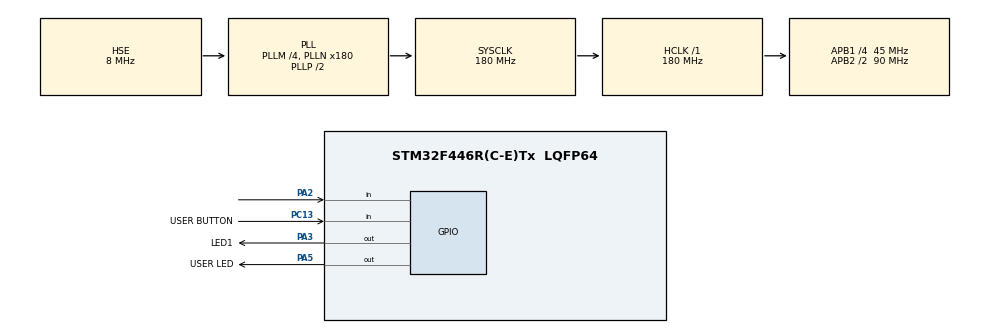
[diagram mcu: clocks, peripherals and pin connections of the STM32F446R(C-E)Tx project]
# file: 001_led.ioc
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Mcu.Family=STM32F4
Mcu.Name=STM32F446R(C-E)Tx
Mcu.Package=LQFP64
NVIC.PriorityGroup=NVIC_PRIORITYGROUP_0
PA2.Signal=GPIO_Input
PA3.GPIO_Label=LED1
PA3.Signal=GPIO_Output
PA5.GPIO_Label=USER LED
PA5.GPIO_ModeDefaultOutputPP=GPIO_MODE_OUTPUT_OD
PA5.GPIO_PuPd=GPIO_PULLUP
PA5.GPIO_Speed=GPIO_SPEED_FREQ_VERY_HIGH
PA5.PinState=GPIO_PIN_SET
PA5.Signal=GPIO_Output
PC13.GPIO_Label=USER BUTTON
PC13.GPIO_PuPd=GPIO_NOPULL
PC13.Signal=GPIO_Input
PH0-OSC_IN.Mode=HSE-External-Oscillator
PH0-OSC_IN.Signal=RCC_OSC_IN
PH1-OSC_OUT.Mode=HSE-External-Oscillator
PH1-OSC_OUT.Signal=RCC_OSC_OUT
ProjectManager.HeapSize=0x200
ProjectManager.StackSize=0x400
ProjectManager.TargetToolchain=STM32CubeIDE
RCC.48MHZClocksFreq_Value=84000000
RCC.AHBFreq_Value=180000000
RCC.APB1CLKDivider=RCC_HCLK_DIV4
RCC.APB1Freq_Value=45000000
RCC.APB1TimFreq_Value=90000000
RCC.APB2CLKDivider=RCC_HCLK_DIV2
RCC.APB2Freq_Value=90000000
RCC.APB2TimFreq_Value=180000000
RCC.CortexFreq_Value=180000000
RCC.FLatency-AdvancedSettings=FLASH_LATENCY_5
RCC.HCLKFreq_Value=180000000
RCC.HSE_VALUE=8000000
RCC.HSI_VALUE=16000000
RCC.PLLM=4
RCC.PLLN=180
RCC.PLLSourceVirtual=RCC_PLLSOURCE_HSE
RCC.SYSCLKFreq_VALUE=180000000
RCC.SYSCLKSource=RCC_SYSCLKSOURCE_PLLCLK
RCC.USBFreq_Value=180000000
RCC.VCOOutputFreq_Value=360000000
board=NUCLEO-F446RE

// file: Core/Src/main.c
/* USER CODE BEGIN Header */
/**
  ******************************************************************************
  * @file           : main.c
  * @brief          : Main program body
  ******************************************************************************
  * @attention
  *
  * Copyright (c) 2026 STMicroelectronics.
  * All rights reserved.
  *
  * This software is licensed under terms that can be found in the LICENSE file
  * in the root directory of this software component.
  * If no LICENSE file comes with this software, it is provided AS-IS.
  *
  ******************************************************************************
  */
/* USER CODE END Header */
#include "main.h"

/* USER CODE BEGIN PV */
uint8_t button_state = 0;
/* USER CODE END PV */

void SystemClock_Config(void);
static void MX_GPIO_Init(void);

int main(void)
{

  /* MCU Configuration--------------------------------------------------------*/

  /* Reset of all peripherals, Initializes the Flash interface and the Systick. */
  HAL_Init();

  /* Configure the system clock */
  SystemClock_Config();

  /* Initialize all configured peripherals */
  MX_GPIO_Init();

  /* Infinite loop */
  while (1)
  {

    /* USER CODE BEGIN 3 */
		   (GPIOA, GPIO_PIN_5, 0);
//
//	  button_state = HAL_GPIO_ReadPin(GPIOC, GPIO_PIN_13);
//
//	  if(HAL_GPIO_ReadPin(GPIOC, GPIO_PIN_13) == 1){
//	  }else{
//		  HAL_GPIO_WritePin(GPIOA, GPIO_PIN_5, 1);
//	  }
//
//	  if(HAL_GPIO_ReadPin(GPIOA, GPIO_PIN_2) == 0){
//		  HAL_GPIO_WritePin(GPIOA, GPIO_PIN_3, 0);
//	  }else{
//		  HAL_GPIO_WritePin(GPIOA, GPIO_PIN_3, 1);
//	  }

//	  HAL_GPIO_TogglePin(GPIOA, GPIO_PIN_5);
//	  HAL_Delay(1000);// 1s -> 1000 ms

  }
  /* USER CODE END 3 */
}

void SystemClock_Config(void)
{
  RCC_OscInitTypeDef RCC_OscInitStruct = {0};
  RCC_ClkInitTypeDef RCC_ClkInitStruct = {0};

  /** Configure the main internal regulator output voltage
  */
  __HAL_RCC_PWR_CLK_ENABLE();
  __HAL_PWR_VOLTAGESCALING_CONFIG(PWR_REGULATOR_VOLTAGE_SCALE1);

  /** Initializes the RCC Oscillators according to the specified parameters
  * in the RCC_OscInitTypeDef structure.
  */
  RCC_OscInitStruct.OscillatorType = RCC_OSCILLATORTYPE_HSE;
  RCC_OscInitStruct.HSEState = RCC_HSE_ON;
  RCC_OscInitStruct.PLL.PLLState = RCC_PLL_ON;
  RCC_OscInitStruct.PLL.PLLSource = RCC_PLLSOURCE_HSE;
  RCC_OscInitStruct.PLL.PLLM = 4;
  RCC_OscInitStruct.PLL.PLLN = 180;
  RCC_OscInitStruct.PLL.PLLP = RCC_PLLP_DIV2;
  RCC_OscInitStruct.PLL.PLLQ = 2;
  RCC_OscInitStruct.PLL.PLLR = 2;
  if (HAL_RCC_OscConfig(&RCC_OscInitStruct) != HAL_OK)
  {
    Error_Handler();
  }

  /** Activate the Over-Drive mode
  */
  if (HAL_PWREx_EnableOverDrive() != HAL_OK)
  {
    Error_Handler();
  }

  /** Initializes the CPU, AHB and APB buses clocks
  */
  RCC_ClkInitStruct.ClockType = RCC_CLOCKTYPE_HCLK|RCC_CLOCKTYPE_SYSCLK
                              |RCC_CLOCKTYPE_PCLK1|RCC_CLOCKTYPE_PCLK2;
  RCC_ClkInitStruct.SYSCLKSource = RCC_SYSCLKSOURCE_PLLCLK;
  RCC_ClkInitStruct.AHBCLKDivider = RCC_SYSCLK_DIV1;
  RCC_ClkInitStruct.APB1CLKDivider = RCC_HCLK_DIV4;
  RCC_ClkInitStruct.APB2CLKDivider = RCC_HCLK_DIV2;

  if (HAL_RCC_ClockConfig(&RCC_ClkInitStruct, FLASH_LATENCY_5) != HAL_OK)
  {
    Error_Handler();
  }
}

static void MX_GPIO_Init(void)
{
  GPIO_InitTypeDef GPIO_InitStruct = {0};

  /* GPIO Ports Clock Enable */
  __HAL_RCC_GPIOC_CLK_ENABLE();
  __HAL_RCC_GPIOH_CLK_ENABLE();
  __HAL_RCC_GPIOA_CLK_ENABLE();

  /*Configure GPIO pin Output Level */
  HAL_GPIO_WritePin(LED1_GPIO_Port, LED1_Pin, GPIO_PIN_RESET);

  /*Configure GPIO pin Output Level */
  HAL_GPIO_WritePin(USER_LED_GPIO_Port, USER_LED_Pin, GPIO_PIN_SET);

  /*Configure GPIO pin : USER_BUTTON_Pin */
  GPIO_InitStruct.Pin = USER_BUTTON_Pin;
  GPIO_InitStruct.Mode = GPIO_MODE_INPUT;
  GPIO_InitStruct.Pull = GPIO_NOPULL;
  HAL_GPIO_Init(USER_BUTTON_GPIO_Port, &GPIO_InitStruct);

  /*Configure GPIO pin : PA2 */
  GPIO_InitStruct.Pin = GPIO_PIN_2;
  GPIO_InitStruct.Mode = GPIO_MODE_INPUT;
  GPIO_InitStruct.Pull = GPIO_NOPULL;
  HAL_GPIO_Init(GPIOA, &GPIO_InitStruct);

  /*Configure GPIO pin : LED1_Pin */
  GPIO_InitStruct.Pin = LED1_Pin;
  GPIO_InitStruct.Mode = GPIO_MODE_OUTPUT_PP;
  GPIO_InitStruct.Pull = GPIO_NOPULL;
  GPIO_InitStruct.Speed = GPIO_SPEED_FREQ_LOW;
  HAL_GPIO_Init(LED1_GPIO_Port, &GPIO_InitStruct);

  /*Configure GPIO pin : USER_LED_Pin */
  GPIO_InitStruct.Pin = USER_LED_Pin;
  GPIO_InitStruct.Mode = GPIO_MODE_OUTPUT_OD;
  GPIO_InitStruct.Pull = GPIO_PULLUP;
  GPIO_InitStruct.Speed = GPIO_SPEED_FREQ_VERY_HIGH;
  HAL_GPIO_Init(USER_LED_GPIO_Port, &GPIO_InitStruct);

}

void Error_Handler(void)
{
  __disable_irq();
  while (1)
  {
  }
}
